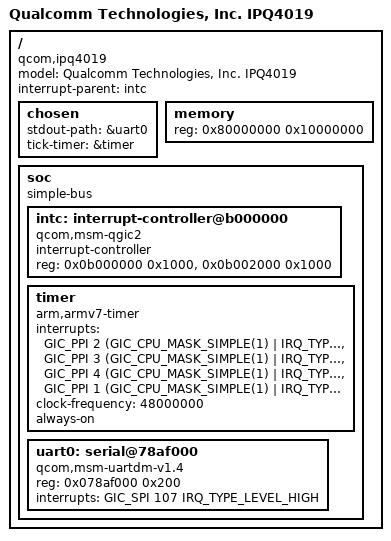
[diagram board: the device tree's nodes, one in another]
/dts-v1/;

#include <dt-bindings/interrupt-controller/arm-gic.h>

/ {
	#address-cells = <1>;
	#size-cells = <1>;
	model = "Qualcomm Technologies, Inc. IPQ4019";
	compatible = "qcom,ipq4019";
	interrupt-parent = <&intc>;

	chosen {
		stdout-path = &uart0;
		tick-timer = &timer;
	};

	memory {
		device_type = "memory";
		reg = <0x80000000 0x10000000>; /* 256MB */
	};

	soc {
		#address-cells = <1>;
		#size-cells = <1>;
		ranges;
		compatible = "simple-bus";

		intc: interrupt-controller@b000000 {
			compatible = "qcom,msm-qgic2";
			interrupt-controller;
			#interrupt-cells = <3>;
			reg = <0x0b000000 0x1000>,
			      <0x0b002000 0x1000>;
		};

		timer: timer {
			compatible = "arm,armv7-timer";
			interrupts = <GIC_PPI 2 (GIC_CPU_MASK_SIMPLE(1) | IRQ_TYPE_LEVEL_LOW)>,
			             <GIC_PPI 3 (GIC_CPU_MASK_SIMPLE(1) | IRQ_TYPE_LEVEL_LOW)>,
			             <GIC_PPI 4 (GIC_CPU_MASK_SIMPLE(1) | IRQ_TYPE_LEVEL_LOW)>,
			             <GIC_PPI 1 (GIC_CPU_MASK_SIMPLE(1) | IRQ_TYPE_LEVEL_LOW)>;
			clock-frequency = <48000000>;
			always-on;
		};

		uart0: serial@78af000 {
			compatible = "qcom,msm-uartdm-v1.4", "qcom,msm-uartdm";
			reg = <0x078af000 0x200>;
			interrupts = <GIC_SPI 107 IRQ_TYPE_LEVEL_HIGH>;
		};
	};
};
